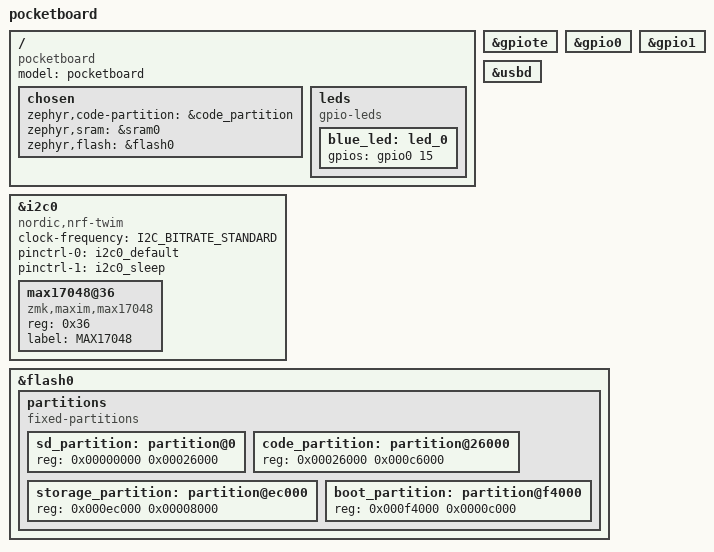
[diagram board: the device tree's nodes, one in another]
/*
 * Copyright (c) 2021 The ZMK Contributors
 *
 * SPDX-License-Identifier: MIT
 */

#include <nordic/nrf52840_qiaa.dtsi>
#include "pocketboard-pinctrl.dtsi"
#include "arduino_pro_micro_pins.dtsi"

/ {
    model = "pocketboard";
    compatible = "pocketboard";

    chosen {
        zephyr,code-partition = &code_partition;
        zephyr,sram = &sram0;
        zephyr,flash = &flash0;
    };

    leds {
        compatible = "gpio-leds";
        blue_led: led_0 {
            gpios = <&gpio0 15 GPIO_ACTIVE_HIGH>;
        };
    };
};

&gpiote {
    status = "okay";
};

&gpio0 {
    status = "okay";
};

&gpio1 {
    status = "okay";
};

&i2c0 {
    compatible = "nordic,nrf-twim";
    status = "okay";
    clock-frequency = <I2C_BITRATE_STANDARD>;
    pinctrl-0 = <&i2c0_default>;
    pinctrl-1 = <&i2c0_sleep>;
    pinctrl-names = "default", "sleep";

    max17048@36 {
        compatible = "zmk,maxim,max17048";
        reg = <0x36>;
        label = "MAX17048";
    };
};

zephyr_udc0: &usbd {
    status = "okay";
};


&flash0 {
    /*
     * For more information, see:
     * http://docs.zephyrproject.org/latest/devices/dts/flash_partitions.html
     */
    partitions {
        compatible = "fixed-partitions";
        #address-cells = <1>;
        #size-cells = <1>;

        sd_partition: partition@0 {
            reg = <0x00000000 0x00026000>;
        };
        code_partition: partition@26000 {
            reg = <0x00026000 0x000c6000>;
        };

        /*
         * The flash starting at 0x000ec000 and ending at
         * 0x000f3fff is reserved for use by the application.
         */

        /*
         * Storage partition will be used by FCB/LittleFS/NVS
         * if enabled.
         */
        storage_partition: partition@ec000 {
            reg = <0x000ec000 0x00008000>;
        };

        boot_partition: partition@f4000 {
            reg = <0x000f4000 0x0000c000>;
        };
    };
};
